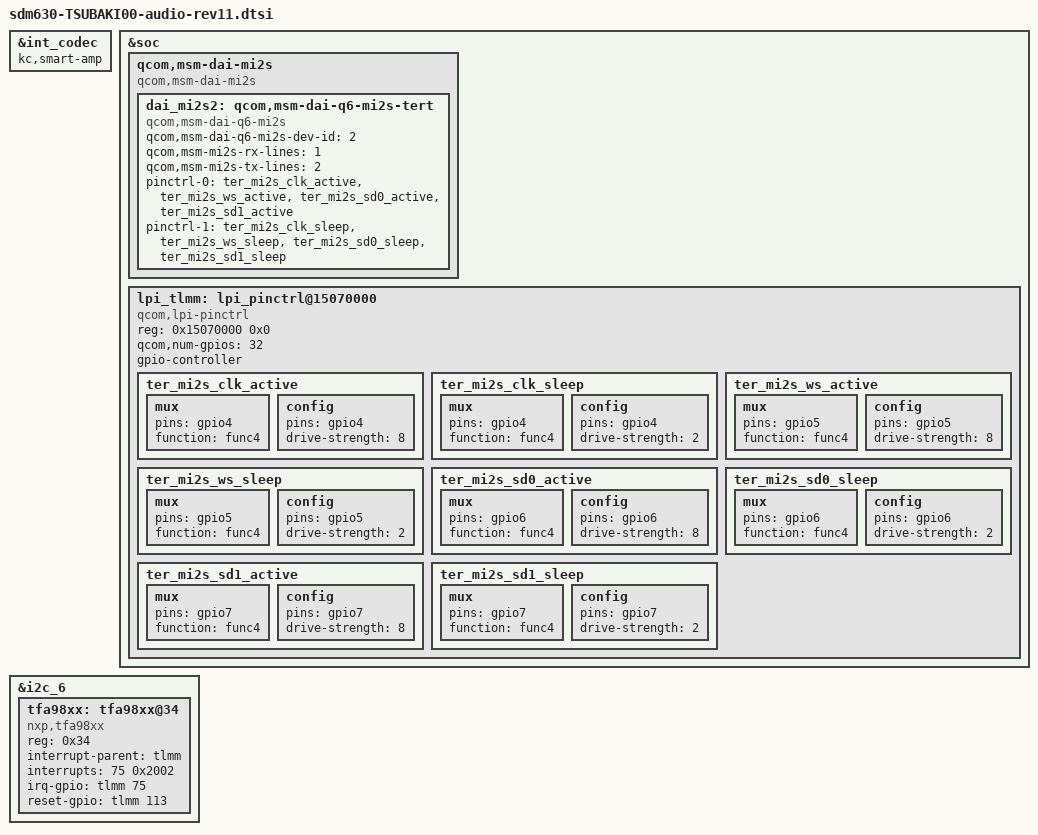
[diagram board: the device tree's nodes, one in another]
/*
 * This software is contributed or developed by KYOCERA Corporation.
 * (C) 2019 KYOCERA Corporation
 *
 * This program is free software; you can redistribute it and/or modify
 * it under the terms of the GNU General Public License version 2 and
 * only version 2 as published by the Free Software Foundation.
 *
 * This program is distributed in the hope that it will be useful,
 * but WITHOUT ANY WARRANTY; without even the implied warranty of
 * MERCHANTABILITY or FITNESS FOR A PARTICULAR PURPOSE.  See the
 * GNU General Public License for more details.
 */

&int_codec {
	kc,smart-amp;
};

&soc {
	qcom,msm-dai-mi2s {
		compatible = "qcom,msm-dai-mi2s";

		dai_mi2s2: qcom,msm-dai-q6-mi2s-tert {
			compatible = "qcom,msm-dai-q6-mi2s";
			qcom,msm-dai-q6-mi2s-dev-id = <2>;
			qcom,msm-mi2s-rx-lines = <1>;
			qcom,msm-mi2s-tx-lines = <2>;
			pinctrl-names = "default","sleep";
			pinctrl-0 = <&ter_mi2s_clk_active &ter_mi2s_ws_active
				&ter_mi2s_sd0_active &ter_mi2s_sd1_active>;
			pinctrl-1 = <&ter_mi2s_clk_sleep &ter_mi2s_ws_sleep
				&ter_mi2s_sd0_sleep &ter_mi2s_sd1_sleep>;
		};
	};
};

&i2c_6 { /* BLSP1 QUP6 (NFC) */
	status = "okay";
	tfa98xx: tfa98xx@34 {
		compatible = "nxp,tfa98xx";
		reg = <0x34>;
		interrupt-parent = <&tlmm>;
		interrupts = <75 0x2002>;
		irq-gpio = <&tlmm 75 0x2008>;
		reset-gpio = <&tlmm 113 0x00>;
	};
};

&soc {
	lpi_tlmm: lpi_pinctrl@15070000 {
		compatible = "qcom,lpi-pinctrl";
		reg = <0x15070000 0x0>;
		qcom,num-gpios = <32>;
		gpio-controller;
		#gpio-cells = <2>;

		ter_mi2s_clk_active: ter_mi2s_clk_active {
			mux {
				pins = "gpio4";
				function = "func4";
			};

			config {
				pins = "gpio4";
				drive-strength = <8>;
			};
		};

		ter_mi2s_clk_sleep: ter_mi2s_clk_sleep {
			mux {
				pins = "gpio4";
				function = "func4";
			};

			config {
				pins = "gpio4";
				drive-strength = <2>;
			};
		};

		ter_mi2s_ws_active: ter_mi2s_ws_active {
			mux {
				pins = "gpio5";
				function = "func4";
			};

			config {
				pins = "gpio5";
				drive-strength = <8>;
			};
		};

		ter_mi2s_ws_sleep: ter_mi2s_ws_sleep {
			mux {
				pins = "gpio5";
				function = "func4";
			};

			config {
				pins = "gpio5";
				drive-strength = <2>;
			};
		};
		ter_mi2s_sd0_active: ter_mi2s_sd0_active {
			mux {
				pins = "gpio6";
				function = "func4";
			};

			config {
				pins = "gpio6";
				drive-strength = <8>;
			};
		};

		ter_mi2s_sd0_sleep: ter_mi2s_sd0_sleep {
			mux {
				pins = "gpio6";
				function = "func4";
			};

			config {
				pins = "gpio6";
				drive-strength = <2>;
			};
		};
		ter_mi2s_sd1_active: ter_mi2s_sd1_active {
			mux {
				pins = "gpio7";
				function = "func4";
			};

			config {
				pins = "gpio7";
				drive-strength = <8>;
			};
		};

		ter_mi2s_sd1_sleep: ter_mi2s_sd1_sleep {
			mux {
				pins = "gpio7";
				function = "func4";
			};

			config {
				pins = "gpio7";
				drive-strength = <2>;
			};
		};
	};
};
